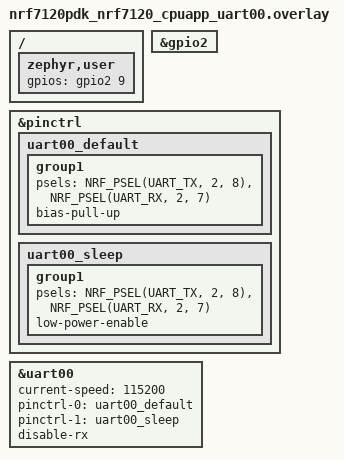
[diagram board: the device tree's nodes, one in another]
/*
 * Test requires wire connection between:
 *  - uart00 TX at P2.08 <-> GPIO input at P2.09
 */

/ {
	zephyr,user {
		gpios = <&gpio2 9 GPIO_ACTIVE_HIGH>;
	};
};

&gpio2 {
	status = "okay";
};

&pinctrl {
	uart00_default: uart00_default {
		group1 {
			psels = <NRF_PSEL(UART_TX, 2, 8)>,
				<NRF_PSEL(UART_RX, 2, 7)>;
				bias-pull-up;
		};
	};

	uart00_sleep: uart00_sleep {
		group1 {
			psels = <NRF_PSEL(UART_TX, 2, 8)>,
				<NRF_PSEL(UART_RX, 2, 7)>;
			low-power-enable;
		};
	};
};

dut: &uart00 {
	status = "okay";
	current-speed = <115200>;
	pinctrl-0 = <&uart00_default>;
	pinctrl-1 = <&uart00_sleep>;
	pinctrl-names = "default", "sleep";
	disable-rx;
};
